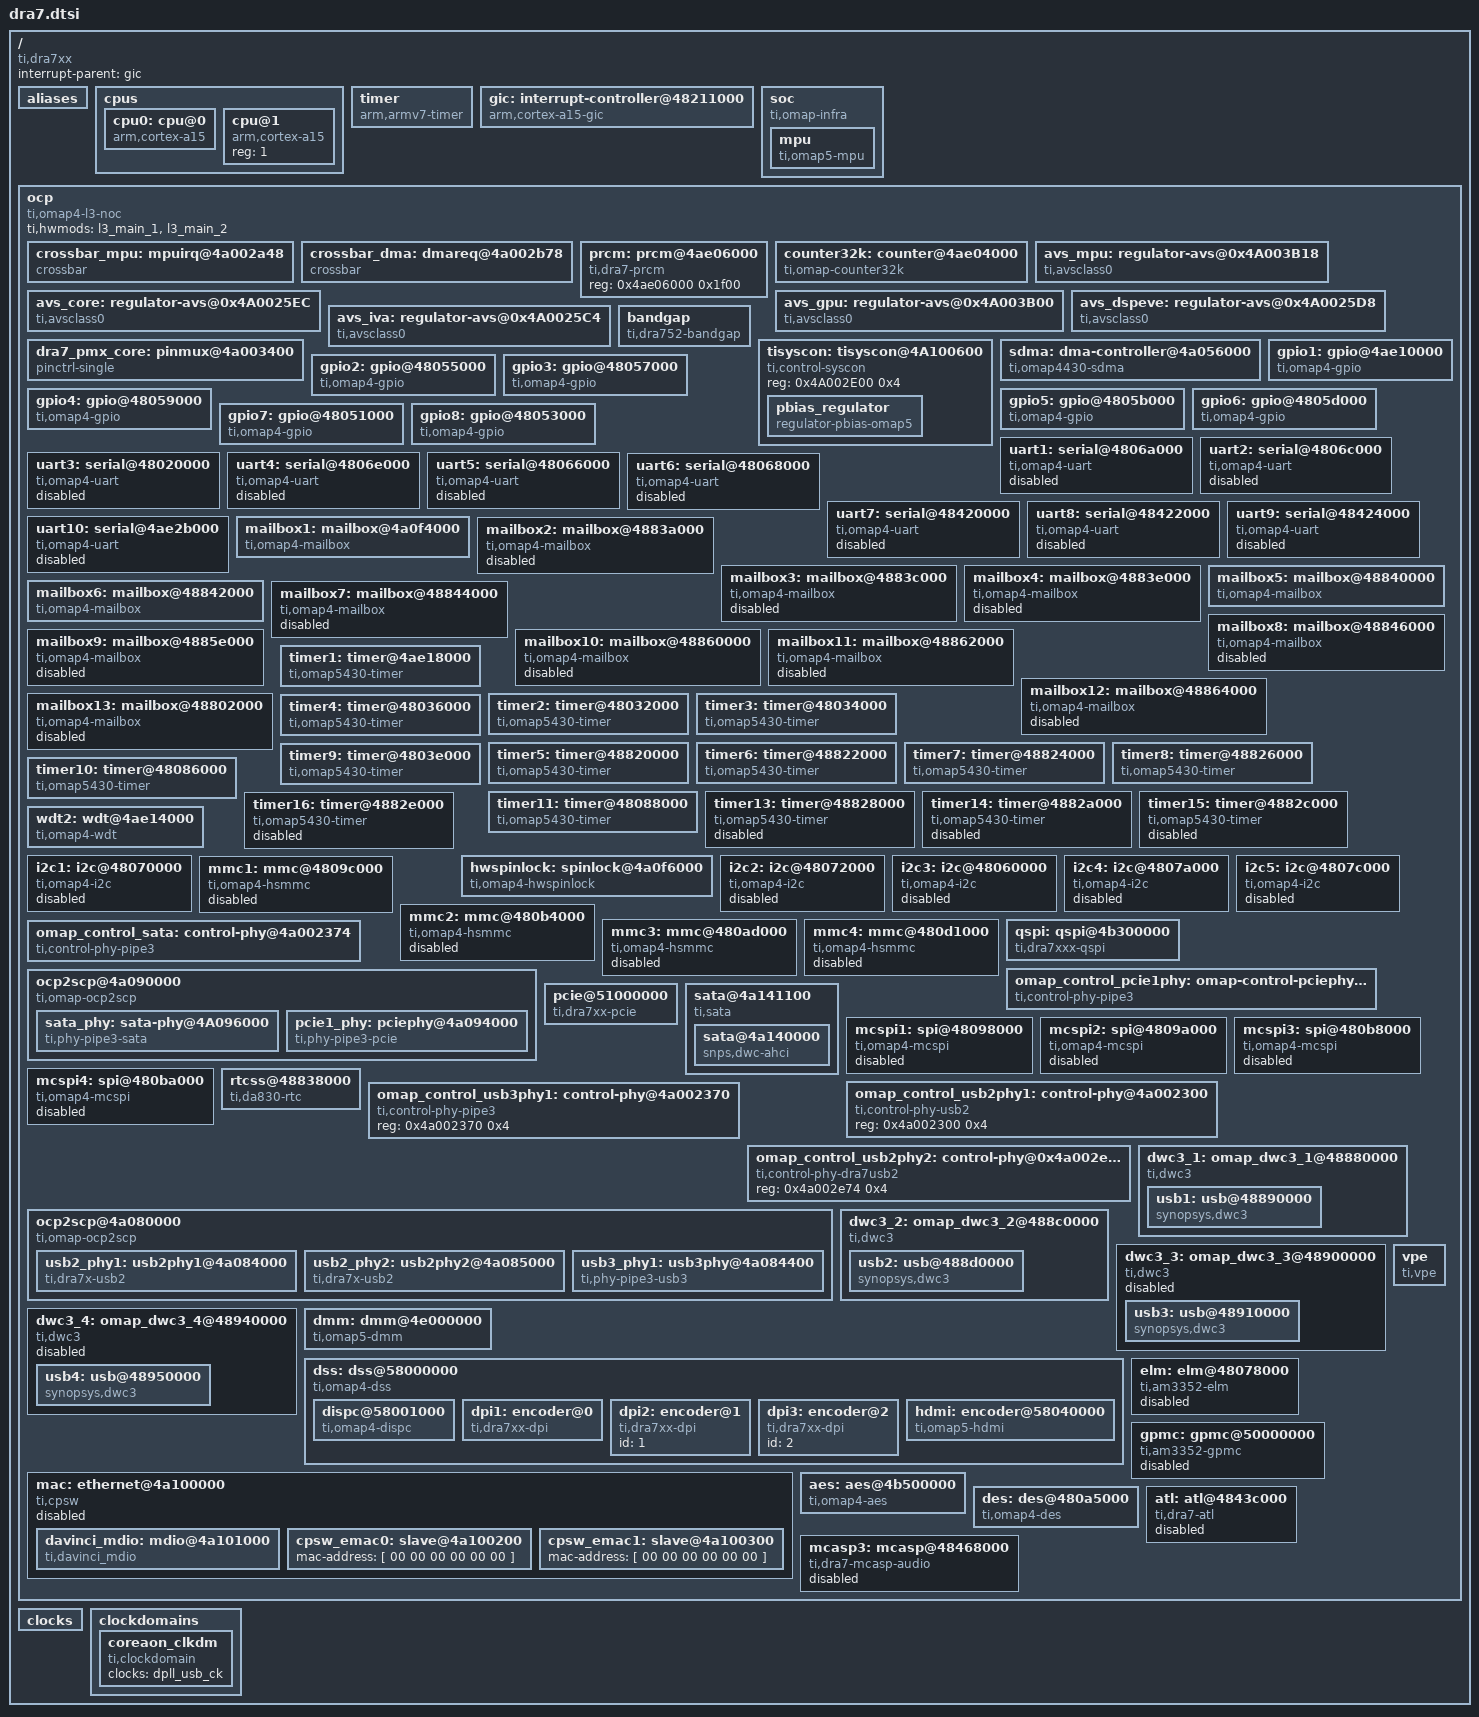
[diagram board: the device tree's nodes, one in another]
/*
 * Copyright (C) 2013 Texas Instruments Incorporated - http://www.ti.com/
 *
 * This program is free software; you can redistribute it and/or modify
 * it under the terms of the GNU General Public License version 2 as
 * published by the Free Software Foundation.
 * Based on "omap4.dtsi"
 */

#include <dt-bindings/interrupt-controller/arm-gic.h>

#include "skeleton.dtsi"

/ {
	compatible = "ti,dra7xx";
	interrupt-parent = <&gic>;

	aliases {
		i2c0 = &i2c1;
		i2c1 = &i2c2;
		i2c2 = &i2c3;
		i2c3 = &i2c4;
		i2c4 = &i2c5;
		serial0 = &uart1;
		serial1 = &uart2;
		serial2 = &uart3;
		serial3 = &uart4;
		serial4 = &uart5;
		serial5 = &uart6;
		ethernet0 = &cpsw_emac0;
		ethernet1 = &cpsw_emac1;
	};

	cpus {
		#address-cells = <1>;
		#size-cells = <0>;

		cpu0: cpu@0 {
			device_type = "cpu";
			compatible = "arm,cortex-a15";
			reg = <0>;

			operating-points = <
				/* kHz    uV */
				1000000	1090000
				1176000	1210000
				>;

			clocks = <&dpll_mpu_ck>;
			clock-names = "cpu";

			clock-latency = <300000>; /* From omap-cpufreq driver */
		};
		cpu@1 {
			device_type = "cpu";
			compatible = "arm,cortex-a15";
			reg = <1>;
		};
	};

	timer {
		compatible = "arm,armv7-timer";
		/* PPI secure/nonsecure IRQ */
		interrupts = <GIC_PPI 13 (GIC_CPU_MASK_RAW(3) | IRQ_TYPE_LEVEL_LOW)>,
			     <GIC_PPI 14 (GIC_CPU_MASK_RAW(3) | IRQ_TYPE_LEVEL_LOW)>,
			     <GIC_PPI 11 (GIC_CPU_MASK_RAW(3) | IRQ_TYPE_LEVEL_LOW)>,
			     <GIC_PPI 10 (GIC_CPU_MASK_RAW(3) | IRQ_TYPE_LEVEL_LOW)>;
		clock-frequency = <6144000>;
	};

	gic: interrupt-controller@48211000 {
		compatible = "arm,cortex-a15-gic";
		interrupt-controller;
		#interrupt-cells = <3>;
		reg = <0x48211000 0x1000>,
		      <0x48212000 0x1000>,
		      <0x48214000 0x2000>,
		      <0x48216000 0x2000>;
	};

	/*
	 * The soc node represents the soc top level view. It is uses for IPs
	 * that are not memory mapped in the MPU view or for the MPU itself.
	 */
	soc {
		compatible = "ti,omap-infra";
		mpu {
			compatible = "ti,omap5-mpu";
			ti,hwmods = "mpu";
			clocks = <&dpll_mpu_m2_ck>;
			clock-names = "fck";
		};
	};

	/*
	 * XXX: Use a flat representation of the SOC interconnect.
	 * The real OMAP interconnect network is quite complex.
	 * Since that will not bring real advantage to represent that in DT for
	 * the moment, just use a fake OCP bus entry to represent the whole bus
	 * hierarchy.
	 */
	ocp {
		compatible = "ti,omap4-l3-noc", "simple-bus";
		#address-cells = <1>;
		#size-cells = <1>;
		ranges;
		ti,hwmods = "l3_main_1", "l3_main_2";

		crossbar_mpu: mpuirq@4a002a48 {
			compatible = "crossbar";
			crossbar-name = "mpu-irq";
			reg = <0x4a002a48 0x0130>;
			reg-width = <16>;
			crossbar-lines = "mpu-irq", "rtc-ss-alarm", <0x9f 0xd9 0x12e>,
					 "mpu-irq", "mcasp3-arevt", <0x9e 0x96 0x12c>,
					 "mpu-irq", "mcasp3-axevt", <0x9d 0x97 0x12a>,
					 "mpu-irq", "mailbox5", <0x88 0xfb 0x100>,
					 "mpu-irq", "mailbox6", <0x8d 0xff 0x10a>,
					 "mpu-irq", "qspi", <0x7c 0x157 0x0ec>,
					 "mpu-irq", "vpe", <0x9c 0x162 0x128>,
					 "mpu-irq", "cpsw-rx-thresh", <0x32 0x14e 0x58>,
					 "mpu-irq", "cpsw-rx", <0x33 0x14f 0x5a>,
					 "mpu-irq", "cpsw-tx", <0x34 0x150 0x5c>,
					 "mpu-irq", "cpsw-misc", <0x35 0x151 0x5e>,
					 "mpu-irq", "pcie1-main", <0x81 0xE8 0xF6>,
					 "mpu-irq", "pcie1-msi", <0x86 0xE9 0xFC>,
					 "mpu-irq", "ipu2-mmu", <0x8e 0x18c 0x10c>,
					 "mpu-irq", "dsp1-mmu1", <0x8f 0x91 0x10e>,
					 "mpu-irq", "dsp2-mmu0", <0x90 0x92 0x110>,
					 "mpu-irq", "dsp2-mmu1", <0x91 0x93 0x112>;
		};

		crossbar_dma: dmareq@4a002b78 {
			compatible = "crossbar";
			crossbar-name = "dma-req";
			reg = <0x4a002b78 0x0100>;
			reg-width = <16>;
			crossbar-lines = "dma-req", "mcasp3-tx", <124 133 0xf8>,
					 "dma-req", "mcasp3-rx", <125 132 0xfa>;
		};

		prcm: prcm@4ae06000 {
			compatible = "ti,dra7-prcm";
			reg = <0x4ae06000 0x1f00>;
			#reset-cells = <1>;
		};

		counter32k: counter@4ae04000 {
			compatible = "ti,omap-counter32k";
			reg = <0x4ae04000 0x40>;
			ti,hwmods = "counter_32k";
			clocks = <&wkupaon_iclk_mux>;
			clock-names = "fck";
		};

		avs_mpu: regulator-avs@0x4A003B18 {
			compatible = "ti,avsclass0";
			reg = <0x4A003B18 20>;
			efuse-settings = <1090000 8
			1210000 12
			1280000 16>;
		};

		avs_core: regulator-avs@0x4A0025EC {
			compatible = "ti,avsclass0";
			reg = <0x4A0025EC 20>;
			efuse-settings = <1030000 8>;
		};

		avs_gpu: regulator-avs@0x4A003B00 {
			compatible = "ti,avsclass0";
			reg = <0x4A003B00 20>;
			efuse-settings = <1090000 8
			1210000 12
			1280000 16>;
		};

		avs_dspeve: regulator-avs@0x4A0025D8 {
			compatible = "ti,avsclass0";
			reg = <0x4A0025D8 20>;
			efuse-settings = <1055000 8
			1150000 12
			1250000 16>;
		};

		avs_iva: regulator-avs@0x4A0025C4 {
			compatible = "ti,avsclass0";
			reg = <0x4A0025C4 20>;
			efuse-settings = <1055000 8
			1150000 12
			1250000 16>;
		};

		dra7_pmx_core: pinmux@4a003400 {
			compatible = "pinctrl-single";
			reg = <0x4a003400 0x0464>;
			#address-cells = <1>;
			#size-cells = <0>;
			pinctrl-single,register-width = <32>;
			pinctrl-single,function-mask = <0x3fffffff>;
		};

		bandgap: bandgap {
			reg = <0x4a0021e0 0xc
				0x4a00232c 0xc
				0x4a002380 0x2c
				0x4a0023C0 0x3c
				0x4a002564 0x8
				0x4a002574 0x50>;
			compatible = "ti,dra752-bandgap";
			interrupts = <GIC_SPI 126 IRQ_TYPE_LEVEL_HIGH>;
			#thermal-sensor-cells = <1>;
		};

		tisyscon: tisyscon@4A100600 {
			compatible = "ti,control-syscon", "syscon", "simple-bus";
			reg = <0x4A002E00 0x4>;
				pbias_regulator: pbias_regulator {
					compatible = "regulator-pbias-omap5";
					pbias-reg-offset = <0>;
					regulator-name = "pbias_regulator";
					regulator-min-microvolt = <1800000>;
					regulator-max-microvolt = <3000000>;
					regulator-boot-on;
					startup-delay-us = <10>;
			};
		};

		sdma: dma-controller@4a056000 {
			compatible = "ti,omap4430-sdma";
			reg = <0x4a056000 0x1000>;
			interrupts = <0 12 0x4>,
				     <0 13 0x4>,
				     <0 14 0x4>,
				     <0 15 0x4>;
			#dma-cells = <1>;
			#dma-channels = <32>;
			#dma-requests = <127>;
			clocks = <&l3_iclk_div>;
			clock-names = "fck";
		};

		gpio1: gpio@4ae10000 {
			compatible = "ti,omap4-gpio";
			reg = <0x4ae10000 0x200>;
			interrupts = <0 29 0x4>;
			ti,hwmods = "gpio1";
			clocks = <&wkupaon_iclk_mux>, <&gpio1_dbclk>;
			clock-names = "fck", "dbclk";
			gpio-controller;
			#gpio-cells = <2>;
			interrupt-controller;
			#interrupt-cells = <1>;
		};

		gpio2: gpio@48055000 {
			compatible = "ti,omap4-gpio";
			reg = <0x48055000 0x200>;
			interrupts = <0 30 0x4>;
			ti,hwmods = "gpio2";
			clocks = <&l3_iclk_div>, <&gpio2_dbclk>;
			clock-names = "fck", "dbclk";
			gpio-controller;
			#gpio-cells = <2>;
			interrupt-controller;
			#interrupt-cells = <1>;
		};

		gpio3: gpio@48057000 {
			compatible = "ti,omap4-gpio";
			reg = <0x48057000 0x200>;
			interrupts = <0 31 0x4>;
			ti,hwmods = "gpio3";
			clocks = <&l3_iclk_div>, <&gpio3_dbclk>;
			clock-names = "fck", "dbclk";
			gpio-controller;
			#gpio-cells = <2>;
			interrupt-controller;
			#interrupt-cells = <1>;
		};

		gpio4: gpio@48059000 {
			compatible = "ti,omap4-gpio";
			reg = <0x48059000 0x200>;
			interrupts = <0 32 0x4>;
			ti,hwmods = "gpio4";
			clocks = <&l3_iclk_div>, <&gpio4_dbclk>;
			clock-names = "fck", "dbclk";
			gpio-controller;
			#gpio-cells = <2>;
			interrupt-controller;
			#interrupt-cells = <1>;
		};

		gpio5: gpio@4805b000 {
			compatible = "ti,omap4-gpio";
			reg = <0x4805b000 0x200>;
			interrupts = <0 33 0x4>;
			ti,hwmods = "gpio5";
			clocks = <&l3_iclk_div>, <&gpio5_dbclk>;
			clock-names = "fck", "dbclk";
			gpio-controller;
			#gpio-cells = <2>;
			interrupt-controller;
			#interrupt-cells = <1>;
		};

		gpio6: gpio@4805d000 {
			compatible = "ti,omap4-gpio";
			reg = <0x4805d000 0x200>;
			interrupts = <0 34 0x4>;
			ti,hwmods = "gpio6";
			clocks = <&l3_iclk_div>, <&gpio6_dbclk>;
			clock-names = "fck", "dbclk";
			gpio-controller;
			#gpio-cells = <2>;
			interrupt-controller;
			#interrupt-cells = <1>;
		};

		gpio7: gpio@48051000 {
			compatible = "ti,omap4-gpio";
			reg = <0x48051000 0x200>;
			interrupts = <0 35 0x4>;
			ti,hwmods = "gpio7";
			clocks = <&l3_iclk_div>, <&gpio7_dbclk>;
			clock-names = "fck", "dbclk";
			gpio-controller;
			#gpio-cells = <2>;
			interrupt-controller;
			#interrupt-cells = <1>;
		};

		gpio8: gpio@48053000 {
			compatible = "ti,omap4-gpio";
			reg = <0x48053000 0x200>;
			interrupts = <0 121 0x4>;
			ti,hwmods = "gpio8";
			clocks = <&l3_iclk_div>, <&gpio8_dbclk>;
			clock-names = "fck", "dbclk";
			gpio-controller;
			#gpio-cells = <2>;
			interrupt-controller;
			#interrupt-cells = <1>;
		};

		uart1: serial@4806a000 {
			compatible = "ti,omap4-uart";
			reg = <0x4806a000 0x100>;
			interrupts = <0 72 0x4>;
			ti,hwmods = "uart1";
			clocks = <&uart1_gfclk_mux>;
			clock-names = "fck";
			clock-frequency = <48000000>;
			status = "disabled";
		};

		uart2: serial@4806c000 {
			compatible = "ti,omap4-uart";
			reg = <0x4806c000 0x100>;
			interrupts = <0 73 0x4>;
			ti,hwmods = "uart2";
			clocks = <&uart2_gfclk_mux>;
			clock-names = "fck";
			clock-frequency = <48000000>;
			status = "disabled";
		};

		uart3: serial@48020000 {
			compatible = "ti,omap4-uart";
			reg = <0x48020000 0x100>;
			interrupts = <0 74 0x4>;
			ti,hwmods = "uart3";
			clocks = <&uart3_gfclk_mux>;
			clock-names = "fck";
			clock-frequency = <48000000>;
			status = "disabled";
		};

		uart4: serial@4806e000 {
			compatible = "ti,omap4-uart";
			reg = <0x4806e000 0x100>;
			interrupts = <0 70 0x4>;
			ti,hwmods = "uart4";
			clocks = <&uart4_gfclk_mux>;
			clock-names = "fck";
			clock-frequency = <48000000>;
                        status = "disabled";
		};

		uart5: serial@48066000 {
			compatible = "ti,omap4-uart";
			reg = <0x48066000 0x100>;
			interrupts = <0 105 0x4>;
			ti,hwmods = "uart5";
			clocks = <&uart5_gfclk_mux>;
			clock-names = "fck";
			clock-frequency = <48000000>;
			status = "disabled";
		};

		uart6: serial@48068000 {
			compatible = "ti,omap4-uart";
			reg = <0x48068000 0x100>;
			interrupts = <0 106 0x4>;
			ti,hwmods = "uart6";
			clocks = <&uart6_gfclk_mux>;
			clock-names = "fck";
			clock-frequency = <48000000>;
			status = "disabled";
		};

		uart7: serial@48420000 {
			compatible = "ti,omap4-uart";
			reg = <0x48420000 0x100>;
			ti,hwmods = "uart7";
			clock-frequency = <48000000>;
			status = "disabled";
		};

		uart8: serial@48422000 {
			compatible = "ti,omap4-uart";
			reg = <0x48422000 0x100>;
			ti,hwmods = "uart8";
			clock-frequency = <48000000>;
			status = "disabled";
		};

		uart9: serial@48424000 {
			compatible = "ti,omap4-uart";
			reg = <0x48424000 0x100>;
			ti,hwmods = "uart9";
			clock-frequency = <48000000>;
			status = "disabled";
		};

		uart10: serial@4ae2b000 {
			compatible = "ti,omap4-uart";
			reg = <0x4ae2b000 0x100>;
			ti,hwmods = "uart10";
			clock-frequency = <48000000>;
			status = "disabled";
		};

		mailbox1: mailbox@4a0f4000 {
			compatible = "ti,omap4-mailbox";
			reg = <0x4a0f4000 0x200>;
			interrupts = <0 26 0x4>;
			ti,hwmods = "mailbox1";
			ti,mbox-num-users = <3>;
			ti,mbox-num-fifos = <8>;
			#ti,mbox-data-cells = <4>;
			ti,mbox-names = "mbox1-1", "mbox1-2";
			ti,mbox-data = <0 1 0 0>, <3 2 0 0>;
		};

		mailbox2: mailbox@4883a000 {
			compatible = "ti,omap4-mailbox";
			reg = <0x4883a000 0x200>;
			ti,hwmods = "mailbox2";
			ti,mbox-num-users = <4>;
			ti,mbox-num-fifos = <12>;
			#ti,mbox-data-cells = <4>;
			status = "disabled";
		};

		mailbox3: mailbox@4883c000 {
			compatible = "ti,omap4-mailbox";
			reg = <0x4883c000 0x200>;
			ti,hwmods = "mailbox3";
			ti,mbox-num-users = <4>;
			ti,mbox-num-fifos = <12>;
			#ti,mbox-data-cells = <4>;
			status = "disabled";
		};

		mailbox4: mailbox@4883e000 {
			compatible = "ti,omap4-mailbox";
			reg = <0x4883e000 0x200>;
			ti,hwmods = "mailbox4";
			ti,mbox-num-users = <4>;
			ti,mbox-num-fifos = <12>;
			#ti,mbox-data-cells = <4>;
			status = "disabled";
		};

		mailbox5: mailbox@48840000 {
			compatible = "ti,omap4-mailbox";
			reg = <0x48840000 0x200>;
			interrupts = <0 136 0x4>;
			ti,hwmods = "mailbox5";
			ti,mbox-num-users = <4>;
			ti,mbox-num-fifos = <12>;
			#ti,mbox-data-cells = <4>;
			ti,mbox-names = "mbox-ipu1", "mbox-dsp1";
			ti,mbox-data = <6 4 0 2>, <5 1 0 2>;
		};

		mailbox6: mailbox@48842000 {
			compatible = "ti,omap4-mailbox";
			reg = <0x48842000 0x200>;
			interrupts = <0 141 0x4>;
			ti,hwmods = "mailbox6";
			ti,mbox-num-users = <4>;
			ti,mbox-num-fifos = <12>;
			#ti,mbox-data-cells = <4>;
			ti,mbox-names = "mbox-ipu2", "mbox-dsp2";
			ti,mbox-data = <6 4 0 2>, <5 1 0 2>;
		};

		mailbox7: mailbox@48844000 {
			compatible = "ti,omap4-mailbox";
			reg = <0x48844000 0x200>;
			ti,hwmods = "mailbox7";
			ti,mbox-num-users = <4>;
			ti,mbox-num-fifos = <12>;
			#ti,mbox-data-cells = <4>;
			status = "disabled";
		};

		mailbox8: mailbox@48846000 {
			compatible = "ti,omap4-mailbox";
			reg = <0x48846000 0x200>;
			ti,hwmods = "mailbox8";
			ti,mbox-num-users = <4>;
			ti,mbox-num-fifos = <12>;
			#ti,mbox-data-cells = <4>;
			status = "disabled";
		};

		mailbox9: mailbox@4885e000 {
			compatible = "ti,omap4-mailbox";
			reg = <0x4885e000 0x200>;
			ti,hwmods = "mailbox9";
			ti,mbox-num-users = <4>;
			ti,mbox-num-fifos = <12>;
			#ti,mbox-data-cells = <4>;
			status = "disabled";
		};

		mailbox10: mailbox@48860000 {
			compatible = "ti,omap4-mailbox";
			reg = <0x48860000 0x200>;
			ti,hwmods = "mailbox10";
			ti,mbox-num-users = <4>;
			ti,mbox-num-fifos = <12>;
			#ti,mbox-data-cells = <4>;
			status = "disabled";
		};

		mailbox11: mailbox@48862000 {
			compatible = "ti,omap4-mailbox";
			reg = <0x48862000 0x200>;
			ti,hwmods = "mailbox11";
			ti,mbox-num-users = <4>;
			ti,mbox-num-fifos = <12>;
			#ti,mbox-data-cells = <4>;
			status = "disabled";
		};

		mailbox12: mailbox@48864000 {
			compatible = "ti,omap4-mailbox";
			reg = <0x48864000 0x200>;
			ti,hwmods = "mailbox12";
			ti,mbox-num-users = <4>;
			ti,mbox-num-fifos = <12>;
			#ti,mbox-data-cells = <4>;
			status = "disabled";
		};

		mailbox13: mailbox@48802000 {
			compatible = "ti,omap4-mailbox";
			reg = <0x48802000 0x200>;
			ti,hwmods = "mailbox13";
			ti,mbox-num-users = <4>;
			ti,mbox-num-fifos = <12>;
			#ti,mbox-data-cells = <4>;
			status = "disabled";
		};

		timer1: timer@4ae18000 {
			compatible = "ti,omap5430-timer";
			reg = <0x4ae18000 0x80>;
			interrupts = <0 37 0x4>;
			ti,hwmods = "timer1";
			clocks = <&timer1_gfclk_mux>, <&sys_clkin2>;
			clock-names = "fck", "timer_sys_ck";
			ti,timer-alwon;
		};

		timer2: timer@48032000 {
			compatible = "ti,omap5430-timer";
			reg = <0x48032000 0x80>;
			interrupts = <0 38 0x4>;
			ti,hwmods = "timer2";
			clocks = <&timer2_gfclk_mux>, <&sys_clkin2>;
			clock-names = "fck", "timer_sys_ck";
		};

		timer3: timer@48034000 {
			compatible = "ti,omap5430-timer";
			reg = <0x48034000 0x80>;
			interrupts = <0 39 0x4>;
			ti,hwmods = "timer3";
			clocks = <&timer3_gfclk_mux>, <&sys_clkin2>;
			clock-names = "fck", "timer_sys_ck";
			ti,timer-ipu;
		};

		timer4: timer@48036000 {
			compatible = "ti,omap5430-timer";
			reg = <0x48036000 0x80>;
			interrupts = <0 40 0x4>;
			ti,hwmods = "timer4";
			clocks = <&timer4_gfclk_mux>, <&sys_clkin2>;
			clock-names = "fck", "timer_sys_ck";
			ti,timer-ipu;
		};

		timer5: timer@48820000 {
			compatible = "ti,omap5430-timer";
			reg = <0x48820000 0x80>;
			interrupts = <0 41 0x4>;
			ti,hwmods = "timer5";
			clocks = <&timer5_gfclk_mux>, <&timer_sys_clk_div>;
			clock-names = "fck", "timer_sys_ck";
			ti,timer-dsp;
		};

		timer6: timer@48822000 {
			compatible = "ti,omap5430-timer";
			reg = <0x48822000 0x80>;
			interrupts = <0 42 0x4>;
			ti,hwmods = "timer6";
			clocks = <&timer6_gfclk_mux>, <&timer_sys_clk_div>;
			clock-names = "fck", "timer_sys_ck";
			ti,timer-dsp;
			ti,timer-pwm;
		};

		timer7: timer@48824000 {
			compatible = "ti,omap5430-timer";
			reg = <0x48824000 0x80>;
			interrupts = <0 43 0x4>;
			ti,hwmods = "timer7";
			clocks = <&timer7_gfclk_mux>, <&timer_sys_clk_div>;
			clock-names = "fck", "timer_sys_ck";
			ti,timer-dsp;
		};

		timer8: timer@48826000 {
			compatible = "ti,omap5430-timer";
			reg = <0x48826000 0x80>;
			interrupts = <0 44 0x4>;
			ti,hwmods = "timer8";
			clocks = <&timer8_gfclk_mux>, <&timer_sys_clk_div>;
			clock-names = "fck", "timer_sys_ck";
			ti,timer-dsp;
			ti,timer-pwm;
		};

		timer9: timer@4803e000 {
			compatible = "ti,omap5430-timer";
			reg = <0x4803e000 0x80>;
			interrupts = <0 45 0x4>;
			ti,hwmods = "timer9";
			clocks = <&timer9_gfclk_mux>, <&sys_clkin2>;
			clock-names = "fck", "timer_sys_ck";
			ti,timer-ipu;
		};

		timer10: timer@48086000 {
			compatible = "ti,omap5430-timer";
			reg = <0x48086000 0x80>;
			interrupts = <0 46 0x4>;
			ti,hwmods = "timer10";
			clocks = <&timer10_gfclk_mux>, <&sys_clkin2>;
			clock-names = "fck", "timer_sys_ck";
		};

		timer11: timer@48088000 {
			compatible = "ti,omap5430-timer";
			reg = <0x48088000 0x80>;
			interrupts = <0 47 0x4>;
			ti,hwmods = "timer11";
			clocks = <&timer11_gfclk_mux>, <&sys_clkin2>;
			clock-names = "fck", "timer_sys_ck";
			ti,timer-ipu;
			ti,timer-pwm;
		};

		timer13: timer@48828000 {
			compatible = "ti,omap5430-timer";
			reg = <0x48828000 0x80>;
			ti,hwmods = "timer13";
			status = "disabled";
		};

		timer14: timer@4882a000 {
			compatible = "ti,omap5430-timer";
			reg = <0x4882a000 0x80>;
			ti,hwmods = "timer14";
			status = "disabled";
		};

		timer15: timer@4882c000 {
			compatible = "ti,omap5430-timer";
			reg = <0x4882c000 0x80>;
			ti,hwmods = "timer15";
			status = "disabled";
		};

		timer16: timer@4882e000 {
			compatible = "ti,omap5430-timer";
			reg = <0x4882e000 0x80>;
			ti,hwmods = "timer16";
			status = "disabled";
		};

		wdt2: wdt@4ae14000 {
			compatible = "ti,omap4-wdt";
			reg = <0x4ae14000 0x80>;
			interrupts = <0 80 0x4>;
			ti,hwmods = "wd_timer2";
			clocks = <&sys_32k_ck>;
			clock-names = "fck";
		};

		hwspinlock: spinlock@4a0f6000 {
			compatible = "ti,omap4-hwspinlock";
			reg = <0x4a0f6000 0x1000>;
			ti,hwmods = "spinlock";
		};

		i2c1: i2c@48070000 {
			compatible = "ti,omap4-i2c";
			reg = <0x48070000 0x100>;
			interrupts = <0 56 0x4>;
			#address-cells = <1>;
			#size-cells = <0>;
			ti,hwmods = "i2c1";
			clocks = <&func_96m_fclk>;
			clock-names = "fck";
			status = "disabled";
		};

		i2c2: i2c@48072000 {
			compatible = "ti,omap4-i2c";
			reg = <0x48072000 0x100>;
			interrupts = <0 57 0x4>;
			#address-cells = <1>;
			#size-cells = <0>;
			ti,hwmods = "i2c2";
			clocks = <&func_96m_fclk>;
			clock-names = "fck";
			status = "disabled";
		};

		i2c3: i2c@48060000 {
			compatible = "ti,omap4-i2c";
			reg = <0x48060000 0x100>;
			interrupts = <0 61 0x4>;
			#address-cells = <1>;
			#size-cells = <0>;
			ti,hwmods = "i2c3";
			clocks = <&func_96m_fclk>;
			clock-names = "fck";
			status = "disabled";
		};

		i2c4: i2c@4807a000 {
			compatible = "ti,omap4-i2c";
			reg = <0x4807a000 0x100>;
			interrupts = <0 62 0x4>;
			#address-cells = <1>;
			#size-cells = <0>;
			ti,hwmods = "i2c4";
			clocks = <&func_96m_fclk>;
			clock-names = "fck";
			status = "disabled";
		};

		i2c5: i2c@4807c000 {
			compatible = "ti,omap4-i2c";
			reg = <0x4807c000 0x100>;
			interrupts = <0 60 0x4>;
			#address-cells = <1>;
			#size-cells = <0>;
			ti,hwmods = "i2c5";
			clocks = <&func_96m_fclk>;
			clock-names = "fck";
			status = "disabled";
		};

		mmc1: mmc@4809c000 {
			compatible = "ti,omap4-hsmmc";
			reg = <0x4809c000 0x400>;
			interrupts = <0 83 0x4>;
			ti,hwmods = "mmc1";
			clocks = <&mmc1_fclk_div>, <&mmc1_clk32k>;
			clock-names = "fck", "clk32k";
			ti,dual-volt;
			ti,needs-special-reset;
			dmas = <&sdma 61>, <&sdma 62>;
			dma-names = "tx", "rx";
			status = "disabled";
		};

		mmc2: mmc@480b4000 {
			compatible = "ti,omap4-hsmmc";
			reg = <0x480b4000 0x400>;
			interrupts = <0 86 0x4>;
			ti,hwmods = "mmc2";
			clocks = <&mmc2_fclk_div>, <&mmc2_clk32k>;
			clock-names = "fck", "clk32k";
			ti,needs-special-reset;
			dmas = <&sdma 47>, <&sdma 48>;
			dma-names = "tx", "rx";
			status = "disabled";
		};

		mmc3: mmc@480ad000 {
			compatible = "ti,omap4-hsmmc";
			reg = <0x480ad000 0x400>;
			interrupts = <0 94 0x4>;
			ti,hwmods = "mmc3";
			clocks = <&mmc3_gfclk_div>, <&mmc3_clk32k>;
			clock-names = "fck", "clk32k";
			ti,needs-special-reset;
			dmas = <&sdma 77>, <&sdma 78>;
			dma-names = "tx", "rx";
			status = "disabled";
		};

		mmc4: mmc@480d1000 {
			compatible = "ti,omap4-hsmmc";
			reg = <0x480d1000 0x400>;
			interrupts = <0 96 0x4>;
			ti,hwmods = "mmc4";
			clocks = <&mmc4_gfclk_div>, <&mmc4_clk32k>;
			clock-names = "fck", "clk32k";
			ti,needs-special-reset;
			dmas = <&sdma 57>, <&sdma 58>;
			dma-names = "tx", "rx";
			status = "disabled";
		};

		qspi: qspi@4b300000 {
			compatible = "ti,dra7xxx-qspi";
			reg = <0x4b300000 0x100>, <0x4a002558 0x4>,
				<0x5c000000 0x3ffffff>;
			reg-names = "qspi_base",
				"qspi_ctrlmod",
				"qspi_mmap";
			#address-cells = <1>;
			#size-cells = <0>;
			ti,hwmods = "qspi";
			clocks = <&qspi_gfclk_div>;
			clock-names = "fck";
			ti,spi-num-cs = <4>;
			interrupts = <0 124 0x4>;
			mmap_read;
		};

		omap_control_sata: control-phy@4a002374 {
			compatible = "ti,control-phy-pipe3";
			reg = <0x4a002374 0x4>;
			reg-names = "power";
			clocks = <&sys_clkin1>;
			clock-names = "sysclk";
		};

		omap_control_pcie1phy: omap-control-pciephy@0x4a003c40 {
			compatible = "ti,control-phy-pipe3";
			reg = <0x4a003c40 0x4>;
			reg-names = "power";
			clocks = <&sys_clkin1>;
			clock-names = "sysclk";
		};

		ocp2scp@4a090000 {
			compatible = "ti,omap-ocp2scp";
			#address-cells = <1>;
			#size-cells = <1>;
			ranges;
			ti,hwmods = "ocp2scp3";
			reg = <0x4a090000 0x400>;	/* ocp2scp3 */
			sata_phy: sata-phy@4A096000 {
				compatible = "ti,phy-pipe3-sata";
				reg = <0x4A096000 0x80>, /* phy_rx */
				      <0x4A096400 0x64>, /* phy_tx */
				      <0x4A096800 0x40>; /* pll_ctrl */
				reg-names = "phy_rx", "phy_tx", "pll_ctrl";
				ctrl-module = <&omap_control_sata>;
				clocks = <&sata_ref_clk>;
				clock-names = "refclk";
				#phy-cells = <0>;
			};

			pcie1_phy: pciephy@4a094000 {
				compatible = "ti,phy-pipe3-pcie";
				ctrl-module = <&omap_control_pcie1phy>;
				clocks = <&dpll_pcie_ref_ck>,
					 <&dpll_pcie_ref_m2ldo_ck>,
					 <&optfclk_pciephy_32khz>,
					 <&optfclk_pciephy_clk>,
					 <&optfclk_pciephy_div_clk>,
					 <&optfclk_pciephy_div>,
					 <&l4_root_clk_div>;
				clock-names = "dpll_ref", "dpll_ref_m2",
					      "wkupclk", "refclk",
					      "refclk2", "pcie-phy-div",
					      "fck";
				#phy-cells = <0>;
				ti,hwmods = "pcie1-phy";
			};
		};

		pcie@51000000 {
			compatible = "ti,dra7xx-pcie";
			reg = <0x51002000 0x14c>, <0x51000000 0x2000>, <0x4A002540 0x1f>;
			reg-names = "ti_conf", "rc_dbics", "mmr_unlock";
			interrupts = <0 129 0x4>, <0 134 0x4>;
			clocks = <&l4_root_clk_div>;
			clock-names = "fck";
			#address-cells = <3>;
			#size-cells = <2>;
			device_type = "pci";
			ti,device_type = <3>;
			ranges = <0x00000800 0 0x20001000 0x20001000 0 0x00001000
				  0x81000000 0 0	  0x20002000 0 0x00010000
				  0x82000000 0 0x20012000 0x20012000 0 0xffee000>;
			#interrupt-cells = <1>;
			base-mask = <0x00000000 0x0fffffff>;
			num-lanes = <1>;
			interrupt-map-mask = <0 0 0 0>;
			interrupt-map = <0x0 0 &gic 134>;
			ti,hwmods = "pcie1";
			phys = <&pcie1_phy>;
			phy-names = "pcie-phy1";
			resets = <&prcm 0>;
			reset-names = "reset";
                };

		sata@4a141100 {
			compatible = "ti,sata";
			ti,hwmods = "sata";
			reg = <0x4a141100 0x100>;
			clocks = <&func_48m_fclk>;
			clock-names = "fck";
			#address-cells = <1>;
			#size-cells = <1>;
			ranges;
			sata@4a140000 {
				  compatible = "snps,dwc-ahci";
				  reg = <0x4a140000 0x1100>;
				  interrupts = <0 54 0x4>;
				  phys = <&sata_phy>;
				  phy-names = "sata-phy";
			};
		};


		mcspi1: spi@48098000 {
			compatible = "ti,omap4-mcspi";
			reg = <0x48098000 0x200>;
			interrupts = <0 65 0x4>;
			#address-cells = <1>;
			#size-cells = <0>;
			ti,hwmods = "mcspi1";
			clocks = <&func_48m_fclk>;
			clock-names = "fck";
			ti,spi-num-cs = <4>;
			dmas = <&sdma 35>,
			       <&sdma 36>,
			       <&sdma 37>,
			       <&sdma 38>,
			       <&sdma 39>,
			       <&sdma 40>,
			       <&sdma 41>,
			       <&sdma 42>;
			dma-names = "tx0", "rx0", "tx1", "rx1",
				    "tx2", "rx2", "tx3", "rx3";
			status = "disabled";
		};

		mcspi2: spi@4809a000 {
			compatible = "ti,omap4-mcspi";
			reg = <0x4809a000 0x200>;
			interrupts = <0 66 0x4>;
			#address-cells = <1>;
			#size-cells = <0>;
			ti,hwmods = "mcspi2";
			clocks = <&func_48m_fclk>;
			clock-names = "fck";
			ti,spi-num-cs = <2>;
			dmas = <&sdma 43>,
			       <&sdma 44>,
			       <&sdma 45>,
			       <&sdma 46>;
			dma-names = "tx0", "rx0", "tx1", "rx1";
			status = "disabled";
		};

		mcspi3: spi@480b8000 {
			compatible = "ti,omap4-mcspi";
			reg = <0x480b8000 0x200>;
			interrupts = <0 91 0x4>;
			#address-cells = <1>;
			#size-cells = <0>;
			ti,hwmods = "mcspi3";
			clocks = <&func_48m_fclk>;
			clock-names = "fck";
			ti,spi-num-cs = <2>;
			dmas = <&sdma 15>, <&sdma 16>;
			dma-names = "tx0", "rx0";
			status = "disabled";
		};

		mcspi4: spi@480ba000 {
			compatible = "ti,omap4-mcspi";
			reg = <0x480ba000 0x200>;
			interrupts = <0 48 0x4>;
			#address-cells = <1>;
			#size-cells = <0>;
			ti,hwmods = "mcspi4";
			clocks = <&func_48m_fclk>;
			clock-names = "fck";
			ti,spi-num-cs = <1>;
			dmas = <&sdma 70>, <&sdma 71>;
			dma-names = "tx0", "rx0";
			status = "disabled";
		};

		rtcss@48838000 {
			compatible = "ti,da830-rtc";
			reg = <0x48838000 0x100>;
			interrupts = <0 159 0x4>,
				     <0 159 0x4>;
			ti,hwmods = "rtcss";
			clocks = <&sys_32k_ck>;
			clock-names = "fck";
		};

		omap_control_usb2phy1: control-phy@4a002300 {
			compatible = "ti,control-phy-usb2";
			reg = <0x4a002300 0x4>;
			reg-names = "power";
		};

		omap_control_usb3phy1: control-phy@4a002370 {
			compatible = "ti,control-phy-pipe3";
			reg = <0x4a002370 0x4>;
			reg-names = "power";
		};

		omap_control_usb2phy2: control-phy@0x4a002e74 {
			compatible = "ti,control-phy-dra7usb2";
			reg = <0x4a002e74 0x4>;
			reg-names = "power";
		};

		ocp2scp@4a080000 {
			compatible = "ti,omap-ocp2scp";
			#address-cells = <1>;
			#size-cells = <1>;
			ranges;
			ti,hwmods = "ocp2scp1";
			reg = <0x4a080000 0x400>;	/* ocp2scp1 */
			clocks = <&l4_root_clk_div>;
			clock-names = "fck";

			usb2_phy1: usb2phy1@4a084000 {
				compatible = "ti,dra7x-usb2";
				reg = <0x4a084000 0x400>;
				ctrl-module = <&omap_control_usb2phy1>;
				clocks = <&usb_phy1_always_on_clk32k>,
					 <&usb_otg_ss1_refclk960m>;
				clock-names =	"wkupclk",
						"refclk";
				#phy-cells = <0>;
			};

			usb2_phy2: usb2phy2@4a085000 {
				compatible = "ti,dra7x-usb2";
				reg = <0x4a085000 0x400>;
				ctrl-module = <&omap_control_usb2phy2>;
				clocks = <&usb_phy2_always_on_clk32k>,
					 <&usb_otg_ss2_refclk960m>;
				clock-names =	"wkupclk",
						"refclk";
				#phy-cells = <0>;
			};

			usb3_phy1: usb3phy@4a084400 {
				compatible = "ti,phy-pipe3-usb3";
				reg = <0x4a084400 0x80>,
				      <0x4a084800 0x64>,
				      <0x4a084c00 0x40>;
				reg-names = "phy_rx", "phy_tx", "pll_ctrl";
				ctrl-module = <&omap_control_usb3phy1>;
				clocks = <&usb_phy1_always_on_clk32k>,
					 <&usb_otg_ss1_refclk960m>,
					 <&dpll_core_h13x2_ck>;
				clock-names =	"wkupclk",
						"refclk",
						"refclk2";
				#phy-cells = <0>;
			};
		};

		dwc3_1: omap_dwc3_1@48880000 {
			compatible = "ti,dwc3";
			ti,hwmods = "usb_otg_ss1";
			reg = <0x48880000 0x10000>;
			interrupts = <0 77 4>;
			clocks = <&dpll_core_h13x2_ck>;
			clock-names = "fck";
			#address-cells = <1>;
			#size-cells = <1>;
			utmi-mode = <2>;
			ranges;
			usb1: usb@48890000 {
				compatible = "synopsys,dwc3";
				reg = <0x48890000 0x17000>;
				interrupts = <0 76 4>;
				phys = <&usb2_phy1>, <&usb3_phy1>;
				phy-names = "usb2-phy", "usb3-phy";
				tx-fifo-resize;
				maximum-speed = "super-speed";
				dr_mode = "otg";
			};
		};

		dwc3_2: omap_dwc3_2@488c0000 {
			compatible = "ti,dwc3";
			ti,hwmods = "usb_otg_ss2";
			reg = <0x488c0000 0x10000>;
			interrupts = <0 92 4>;
			clocks = <&dpll_core_h13x2_ck>;
			clock-names = "fck";
			#address-cells = <1>;
			#size-cells = <1>;
			utmi-mode = <2>;
			ranges;
			usb2: usb@488d0000 {
				compatible = "synopsys,dwc3";
				reg = <0x488d0000 0x17000>;
				interrupts = <0 78 4>;
				phys = <&usb2_phy2>;
				phy-names = "usb2-phy";
				tx-fifo-resize;
				maximum-speed = "high-speed";
				dr_mode = "otg";
			};
		};

		/* IRQ for DWC3_3 and DWC3_4 need IRQ crossbar */
		dwc3_3: omap_dwc3_3@48900000 {
			compatible = "ti,dwc3";
			ti,hwmods = "usb_otg_ss3";
			reg = <0x48900000 0x10000>;
			clocks = <&dpll_core_h13x2_ck>;
			clock-names = "fck";
		/*	interrupts = <0 TBD 4>; */
			#address-cells = <1>;
			#size-cells = <1>;
			utmi-mode = <2>;
			ranges;
			status = "disabled";
			usb3: usb@48910000 {
				compatible = "synopsys,dwc3";
				reg = <0x48910000 0x17000>;
		/*		interrupts = <0 93 4>; */
				tx-fifo-resize;
				maximum-speed = "high-speed";
				dr_mode = "otg";
			};
		};

		dwc3_4: omap_dwc3_4@48940000 {
			compatible = "ti,dwc3";
			ti,hwmods = "usb_otg_ss4";
			reg = <0x48940000 0x10000>;
			clocks = <&dpll_core_h13x2_ck>;
			clock-names = "fck";
		/*	interrupts = <0 TBD 4>; */
			#address-cells = <1>;
			#size-cells = <1>;
			utmi-mode = <2>;
			ranges;
			status = "disabled";
			usb4: usb@48950000 {
				compatible = "synopsys,dwc3";
				reg = <0x48950000 0x17000>;
		/*		interrupts = <0 TBD 4>; */
				tx-fifo-resize;
				maximum-speed = "high-speed";
				dr_mode = "otg";
			};
		};

		dmm: dmm@4e000000 {
			compatible = "ti,omap5-dmm";
			reg = <0x4e000000 0x800>;
			interrupts = <0 113 0x4>;
			ti,hwmods = "dmm";
		};

		dss: dss@58000000 {
			compatible = "ti,omap4-dss", "simple-bus";
			reg = <0x58000000 0x80>,
			      <0x58004000 0x340>,
			      <0x58009000 0x340>;
			ti,hwmods = "dss_core";
			clocks = <&dss_dss_clk>, <&dss_48mhz_clk>,
				 <&dss_32khz_clk>, <&dss_video1_clk>,
				 <&dss_video2_clk>, <&dss_hdmi_clk>;
			clock-names = "fck", "hdmi_phy_clk",
				      "32khz_clk", "video1_clk",
				      "video2_clk", "hdmi_clk";
			#address-cells = <1>;
			#size-cells = <1>;
			ranges;

			dispc@58001000 {
				compatible = "ti,omap4-dispc";
				reg = <0x58001000 0x1000>;
				interrupts = <0 25 0x4>;
				ti,hwmods = "dss_dispc";
				clocks = <&dss_dss_clk>;
				clock-names = "fck";
			};

			dpi1: encoder@0 {
				compatible = "ti,dra7xx-dpi";
				id = <0>;
				channel = <0>;
			};

			dpi2: encoder@1 {
				compatible = "ti,dra7xx-dpi";
				id = <1>;
			};

			dpi3: encoder@2 {
				compatible = "ti,dra7xx-dpi";
				id = <2>;
			};

			hdmi: encoder@58040000 {
				compatible = "ti,omap5-hdmi";
				reg = <0x58040000 0x100>,
				      <0x58040200 0x40>,
				      <0x58040300 0x40>,
				      <0x58060000 0x19000>;
				reg-names = "hdmi_wp", "hdmi_pllctrl",
					    "hdmi_txphy", "hdmi_core";
				interrupts = <0 101 0x4>;
				ti,hwmods = "dss_hdmi";
				clocks = <&dss_48mhz_clk>, <&dss_hdmi_clk>;
				clock-names = "fck", "sys_clk";
			};
		};

		vpe {
			compatible = "ti,vpe";
			ti,hwmods = "vpe";
			clocks = <&dpll_core_h23x2_ck>;
			clock-names = "fck";
			reg = <0x489d0000 0x120>,
			      <0x489d0300 0x20>,
			      <0x489d0400 0x20>,
			      <0x489d0500 0x20>,
			      <0x489d0600 0x3c>,
			      <0x489d0700 0x80>,
			      <0x489d5700 0x18>,
			      <0x489dd000 0x400>;
			reg-names = "vpe_top",
				    "vpe_chr_us0",
				    "vpe_chr_us1",
				    "vpe_chr_us2",
				    "vpe_dei",
				    "vpe_sc",
				    "vpe_csc",
				    "vpdma";
			interrupts = <0 0x9c 0x4>;
			#address-cells = <1>;
			#size-cells = <0>;
		};

		mac: ethernet@4a100000 {
			compatible = "ti,cpsw";
			ti,hwmods = "gmac";
			clocks = <&dpll_gmac_ck>, <&gmac_gmii_ref_clk_div>;
			clock-names = "fck", "cpts";
			cpdma_channels = <8>;
			ale_entries = <1024>;
			bd_ram_size = <0x2000>;
			no_bd_ram = <0>;
			rx_descs = <64>;
			mac_control = <0x20>;
			slaves = <2>;
			active_slave = <0>;
			cpts_clock_mult = <0x80000000>;
			cpts_clock_shift = <29>;
			reg = <0x48484000 0x800
			       0x48485200 0x100>;
			#address-cells = <1>;
			#size-cells = <1>;
			/*
			 * rx_thresh_pend
			 * rx_pend
			 * tx_pend
			 * misc_pend
			 */
			interrupts = <GIC_SPI 50 IRQ_TYPE_LEVEL_HIGH>,
				     <GIC_SPI 51 IRQ_TYPE_LEVEL_HIGH>,
				     <GIC_SPI 52 IRQ_TYPE_LEVEL_HIGH>,
				     <GIC_SPI 53 IRQ_TYPE_LEVEL_HIGH>;
			ranges;
			status = "disabled";

			davinci_mdio: mdio@4a101000 {
				compatible = "ti,davinci_mdio";
				#address-cells = <1>;
				#size-cells = <0>;
				ti,hwmods = "davinci_mdio";
				clocks = <&dpll_gmac_ck>;
				clock-names = "fck";
				bus_freq = <1000000>;
				reg = <0x48485000 0x100>;
			};

			cpsw_emac0: slave@4a100200 {
				/* Filled in by U-Boot */
				mac-address = [ 00 00 00 00 00 00 ];
			};

			cpsw_emac1: slave@4a100300 {
				/* Filled in by U-Boot */
				mac-address = [ 00 00 00 00 00 00 ];
			};
		};

		elm: elm@48078000 {
			compatible = "ti,am3352-elm";
			/* compatible = "ti,elm"; */
			reg = <0x48078000 0x2000>;
			interrupts = <GIC_SPI 4 IRQ_TYPE_LEVEL_HIGH>;
			ti,hwmods = "elm";
			clocks = <&l3_iclk_div>;
			clock-names = "fck";
			status = "disabled";
		};

		gpmc: gpmc@50000000 {
			compatible = "ti,am3352-gpmc";
		/* 	compatible = "ti,gpmc"; */
			ti,hwmods = "gpmc";
			clocks = <&l3_iclk_div>;
			clock-names = "fck";
			reg = <0x50000000 0x2000>;
			interrupts = <GIC_SPI 20 IRQ_TYPE_LEVEL_HIGH>;
			gpmc,num-cs = <8>;
			gpmc,num-waitpins = <2>;
			#address-cells = <2>;
			#size-cells = <1>;
			status = "disabled";
		};

		aes: aes@4b500000 {
			compatible = "ti,omap4-aes";
			ti,hwmods = "aes";
			reg = <0x4b500000 0xa0>;
			interrupts = <GIC_SPI 85 IRQ_TYPE_LEVEL_HIGH>;
			dmas = <&sdma 111>, <&sdma 110>;
			dma-names = "tx", "rx";
			clocks = <&l3_iclk_div>;
			clock-names = "fck";
		};

		des: des@480a5000 {
			compatible = "ti,omap4-des";
			ti,hwmods = "des";
			reg = <0x480a5000 0xa0>;
			interrupts = <GIC_SPI 82 IRQ_TYPE_LEVEL_HIGH>;
			dmas = <&sdma 117>, <&sdma 116>;
			dma-names = "tx", "rx";
			clocks = <&l3_iclk_div>;
			clock-names = "fck";
		};

		atl: atl@4843c000 {
			compatible = "ti,dra7-atl";
			reg = <0x4843c000 0x3ff>;
			ti,hwmods = "atl";
			ti,provided-clocks = <&atl_clkin0_ck>, <&atl_clkin1_ck>,
					  <&atl_clkin2_ck>, <&atl_clkin3_ck>;
			clocks = <&atl_gfclk_mux>;
			clock-names = "fck";
			status = "disabled";
		};

		mcasp3: mcasp@48468000 {
			compatible = "ti,dra7-mcasp-audio";
			ti,hwmods = "mcasp3";
			reg = <0x48468000 0x2000>;
			reg-names = "mpu";
			interrupts = <0 157 0x4>,	/* Crossbar 151 */
				     <0 158 0x4>;	/* Crossbar 150 */
			interrupts-names = "tx", "rx";
			dmas =	<&sdma 125>,		/* Crossbar 133 */
				<&sdma 126>;		/* Crossbar 132 */
			dma-names = "tx", "rx";
			clocks = <&mcasp3_ahclkx_mux>;
			clock-names = "fck";
			status = "disabled";
		};
	};

	clocks {
		#address-cells = <1>;
		#size-cells = <1>;
		ranges;
		/include/ "dra7xx-clocks.dtsi"
	};

	clockdomains {
		coreaon_clkdm: coreaon_clkdm {
			compatible = "ti,clockdomain";
			clocks = <&dpll_usb_ck>;
		};
	};
};
